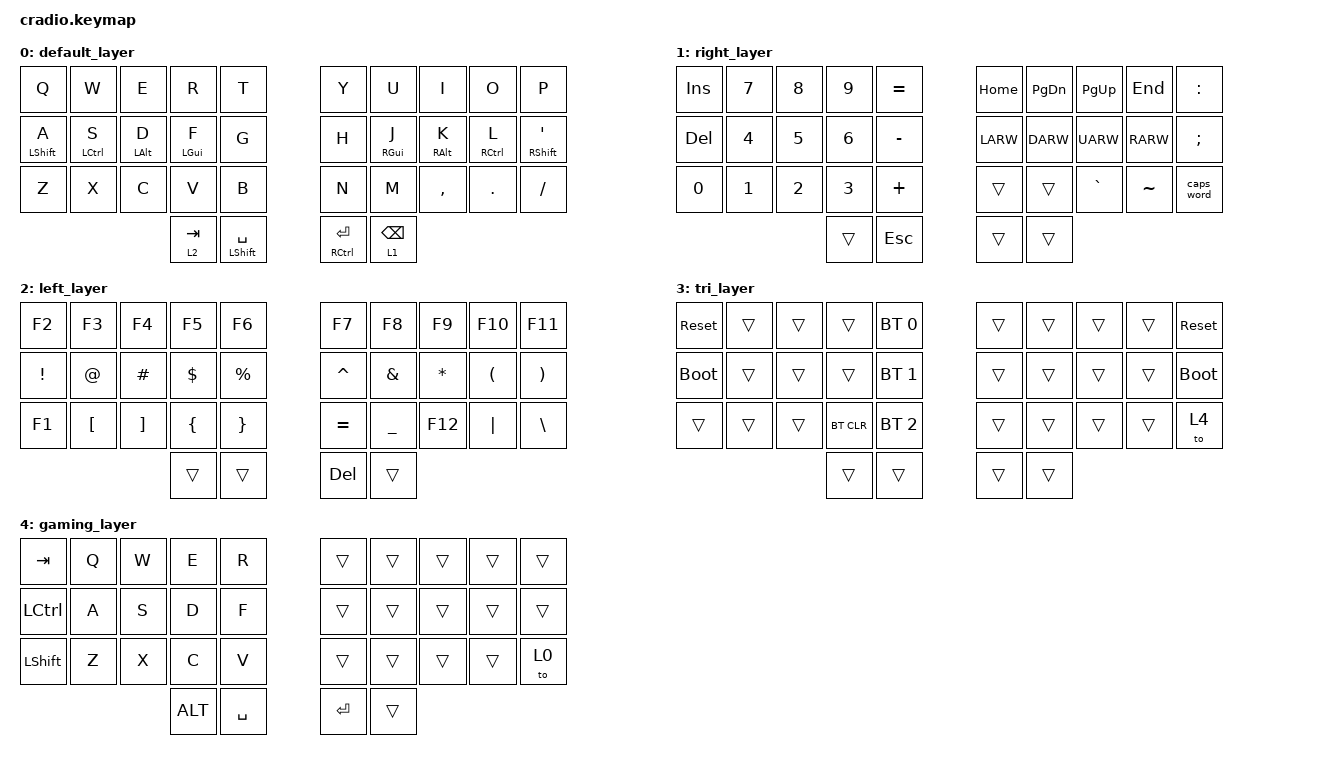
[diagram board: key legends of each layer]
// Copyright (c) 2022 The ZMK Contributors
// SPDX-License-Identifier: MIT

#include <behaviors.dtsi>
#include <dt-bindings/zmk/keys.h>
#include <dt-bindings/zmk/bt.h>

/ {
    behaviors {
        ht: hold_tap {
            compatible = "zmk,behavior-hold-tap";
            #binding-cells = <2>;
            flavor = "tap-preferred";
            tapping-term-ms = <220>;
            quick-tap-ms = <150>;
            require-prior-idle-ms = <100>;
            bindings = <&kp>, <&kp>;
        };
    };

    conditional_layers {
        compatible = "zmk,conditional-layers";
        tri_layer {
            if-layers = <1 2>;
            then-layer = <3>;
        };
    };

    keymap {
        compatible = "zmk,keymap";
        default_layer {
            bindings = <
        //╭──────────┬──────────┬──────────┬──────────┬──────────╮   ╭──────────┬──────────┬──────────┬──────────┬──────────╮
        //│  Q       │  W       │  E       │  R       │  T       │   │  Y       │  U       │  I       │  O       │  P       │
            &kp Q      &kp W      &kp E      &kp R      &kp T          &kp Y      &kp U      &kp I      &kp O      &kp P
        //├──────────┼──────────┼──────────┼──────────┼──────────┤   ├──────────┼──────────┼──────────┼──────────┼──────────┤
        //│  A       │  S       │  D       │  F       │  G       │   │  H       │  J       │  K       │  L       │ ' "      │
        &ht LSHIFT A  &ht LCTRL S &ht LALT D &ht LGUI F  &kp G          &kp H     &ht RGUI J &ht RALT K &ht RCTRL L &ht RSHFT SQT
        //├──────────┼──────────┼──────────┼──────────┼──────────┤   ├──────────┼──────────┼──────────┼──────────┼──────────┤
        //│  Z       │  X       │  C       │  V       │  B       │   │  N       │  M       │ , <      │ . >      │ / ?      │
            &kp Z      &kp X      &kp C      &kp V      &kp B          &kp N      &kp M      &kp COMMA  &kp DOT    &kp FSLH
        //╰──────────┴──────────┴──────────┼──────────┼──────────┤   ├──────────┼──────────┼──────────┴──────────┴──────────╯
                                         &lt 2 TAB &ht LSHFT SPACE &ht RCTRL ENTER  &lt 1 BSPC
        //                                 ╰──────────┴──────────╯   ╰──────────┴──────────╯
            >;
        };

        right_layer {
            bindings = <
        //╭──────────┬──────────┬──────────┬──────────┬──────────╮   ╭──────────┬──────────┬──────────┬──────────┬──────────╮
        //│ INSERT   │  7       │  8       │  9       │  =       │   │ HOME     │ PAGE DN  │ PAGE UP  │ END      │  :       │
            &kp INS    &kp N7     &kp N8     &kp N9     &kp EQUAL      &kp HOME   &kp PG_DN  &kp PG_UP  &kp END    &kp COLON
        //├──────────┼──────────┼──────────┼──────────┼──────────┤   ├──────────┼──────────┼──────────┼──────────┼──────────┤
        //│ DELETE   │  4       │  5       │  6       │  -       │   │ LEFT     │ DOWN     │ UP       │ RIGHT    │  ;       │
            &kp DEL    &kp N4     &kp N5     &kp N6     &kp MINUS      &kp LARW   &kp DARW   &kp UARW   &kp RARW   &kp SEMI
        //├──────────┼──────────┼──────────┼──────────┼──────────┤   ├──────────┼──────────┼──────────┼──────────┼──────────┤
        //│ 0        │  1       │  2       │  3       │  +       │   │          │          │  `       │ ~        │ CAPS     │
           &kp N0      &kp N1     &kp N2     &kp N3     &kp PLUS       &trans     &trans     &kp GRAVE  &kp TILDE  &caps_word
        //╰──────────┴──────────┴──────────┼──────────┼──────────┤   ├──────────┼──────────┼──────────┴──────────┴──────────╯
                                             &trans     &kp ESC        &trans     &trans
        //                                 ╰──────────┴──────────╯   ╰──────────┴──────────╯
            >;
        };
 
        left_layer {
            bindings = <
        //╭──────────┬──────────┬──────────┬──────────┬──────────╮   ╭──────────┬──────────┬──────────┬──────────┬──────────╮
        //│  F2      │  F3      │  F4      │  F5      │  F6      │   │  F7      │  F8      │  F9      │  F10     │  F11     │
            &kp F2     &kp F3     &kp F4     &kp F5     &kp F6         &kp F7     &kp F8     &kp F9     &kp F10    &kp F11
        //├──────────┼──────────┼──────────┼──────────┼──────────┤   ├──────────┼──────────┼──────────┼──────────┼──────────┤
        //│  !       │  @       │  #       │  $       │  %       │   │  ^       │  &       │  *       │  (       │  )       │
            &kp EXCL   &kp AT     &kp HASH   &kp DLLR   &kp PRCNT      &kp CARET  &kp AMPS   &kp ASTRK  &kp LPAR   &kp RPAR 
        //├──────────┼──────────┼──────────┼──────────┼──────────┤   ├──────────┼──────────┼──────────┼──────────┼──────────┤
        //│  F1      │  [       │  ]       │  {       │  }       │   │  =       │  _       │  F12     │  │       │  \       │
            &kp F1     &kp LBKT   &kp RBKT   &kp LBRC   &kp RBRC       &kp EQUAL  &kp UNDER  &kp F12    &kp PIPE   &kp BSLH
        //╰──────────┴──────────┴──────────┼──────────┼──────────┤   ├──────────┼──────────┼──────────┴──────────┴──────────╯
                                             &trans     &trans         &kp DEL    &trans
        //                                 ╰──────────┴──────────╯   ╰──────────┴──────────╯
            >;
        };

        tri_layer {
            bindings = <
        //╭──────────┬──────────┬──────────┬──────────┬──────────╮   ╭──────────┬──────────┬──────────┬──────────┬──────────╮
        //│ RESET    │          │          │          │PROFILE 0 │   │          │          │          │          │  RESET   │
           &sys_reset  &trans     &trans     &trans    &bt BT_SEL 0    &trans     &trans     &trans     &trans    &sys_reset
        //├──────────┼──────────┼──────────┼──────────┼──────────┤   ├──────────┼──────────┼──────────┼──────────┼──────────┤
        //│BOOTLOADER│          │          │          │PROFILE 1 │   │          │          │          │          │BOOTLOADER│
          &bootloader  &trans     &trans     &trans    &bt BT_SEL 1    &trans     &trans     &trans     &trans    &bootloader
        //├──────────┼──────────┼──────────┼──────────┼──────────┤   ├──────────┼──────────┼──────────┼──────────┼──────────┤
        //│          │          │          │ CLEAR BT │PROFILE 2 │   │          │          │          │          │          │
            &trans     &trans     &trans    &bt BT_CLR &bt BT_SEL 2    &trans     &trans      &trans     &trans     &to 4
        //╰──────────┴──────────┴──────────┼──────────┼──────────┤   ├──────────┼──────────┼──────────┴──────────┴──────────╯
                                             &trans     &trans         &trans     &trans
        //                                 ╰──────────┴──────────╯   ╰──────────┴──────────╯
            >;
        };

        gaming_layer {
            bindings = <
        //╭──────────┬──────────┬──────────┬──────────┬──────────╮   ╭──────────┬──────────┬──────────┬──────────┬──────────╮
        //│  TAB     │  Q       │  W       │  E       │  R       │   │          │          │          │          │          │
           &kp TAB     &kp Q      &kp W      &kp E      &kp R          &trans     &trans     &trans     &trans     &trans
        //├──────────┼──────────┼──────────┼──────────┼──────────┤   ├──────────┼──────────┼──────────┼──────────┼──────────┤
        //│  CTRL    │  A       │  S       │  D       │  F       │   │          │          │          │          │          │
           &kp LCTRL   &kp A      &kp S      &kp D      &kp F          &trans     &trans     &trans     &trans     &trans
        //├──────────┼──────────┼──────────┼──────────┼──────────┤   ├──────────┼──────────┼──────────┼──────────┼──────────┤
        //│  SHIFT   │  Z       │  X       │  C       │  V       │   │          │          │          │          │          │
           &kp LSHFT   &kp Z      &kp X      &kp C      &kp V          &trans     &trans     &trans     &trans     &to <0>
        //╰──────────┴──────────┴──────────┼──────────┼──────────┤   ├──────────┼──────────┼──────────┴──────────┴──────────╯
                                             &kp ALT    &kp SPACE      &kp ENTER  &trans
        //                                 ╰──────────┴──────────╯   ╰──────────┴──────────╯
            >;
        };
    };
};
